# M480_v1 register map
File version: 1.0
Registers are 32-bit, read-write, reset 0x0 unless marked. A register's access mark holds for its fields unless they carry their own. Offsets are from the block's base; [hi:lo] are bit positions; {n}, {i} and the like mark numbered series.

## EMAC (part 1 of 2) — EMAC Register Map
Base 0x4000B000
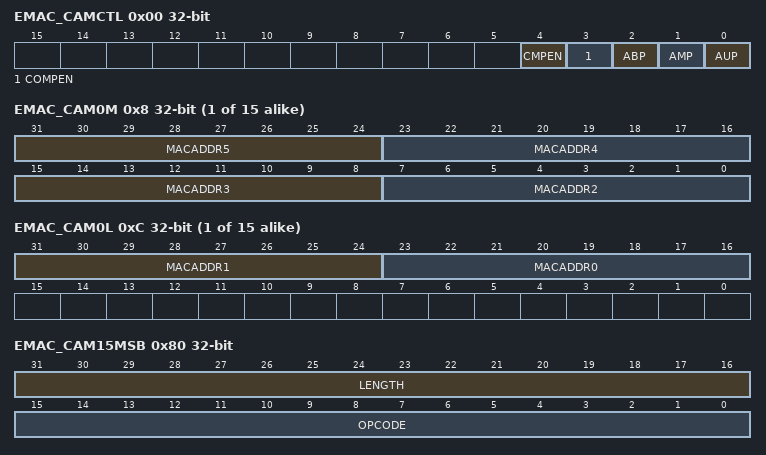
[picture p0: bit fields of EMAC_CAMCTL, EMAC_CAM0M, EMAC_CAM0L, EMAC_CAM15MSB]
0x00 EMAC_CAMCTL — CAM Comparison Control Register
  [4] CMPEN — CAM Compare Enable Bit. The CMPEN controls the enable of CAM comparison function for destination MAC address recognition. If software wants to receive a packet with specific destination MAC address, configures the MAC address into CAM 12~0, then enables that CAM entry and set CMPEN to 1.
    0=CAM comparison function for destination MAC address recognition Disabled; 1=CAM comparison function for destination MAC address recognition Enabled
  [3] COMPEN — Complement CAM Comparison Enable Bit. The COMPEN controls the complement of the CAM comparison result. If the CMPEN and COMPEN are both enabled, the incoming packet with specific destination MAC address configured in CAM entry will be dropped. And the incoming packet with destination MAC address does not configured in any CAM entry will be received.
    0=Complement CAM comparison result Disabled; 1=Complement CAM comparison result Enabled
  [2] ABP — Accept Broadcast Packet. The ABP controls the broadcast packet reception. If ABP is enabled, EMAC receives all incoming packet its destination MAC address is a broadcast address.
    0=EMAC receives packet depends on the CAM comparison result; 1=EMAC receives all broadcast packets
  [1] AMP — Accept Multicast Packet. The AMP controls the multicast packet reception. If AMP is enabled, EMAC receives all incoming packet its destination MAC address is a multicast address.
    0=EMAC receives packet depends on the CAM comparison result; 1=EMAC receives all multicast packets
  [0] AUP — Accept Unicast Packet. The AUP controls the unicast packet reception. If AUP is enabled, EMAC receives all incoming packet its destination MAC address is a unicast address.
    0=EMAC receives packet depends on the CAM comparison result; 1=EMAC receives all unicast packets
0x04 ECAM_CAMEN — CAM Enable Register
  [0] CAMxEN — CAM Entry X Enable Bit. The CAMxEN controls the validation of CAM entry x. The CAM entry 13, 14 and 15 are for PAUSE control frame transmission. If software wants to transmit a PAUSE control frame out to network, the enable bits of these three CAM entries all must be enabled first.
    0=CAM entry x Disabled; 1=CAM entry x Enabled
{0x8+8i} EMAC_CAM{i}M (i=0..14) — CAM{i} Most Significant Word Register
  [31:24] MACADDR5 — MAC Address Byte 5. The CAMxM keeps the bit 47~16 of MAC address. The x can be the 0~14. The register pair {EMAC_CAMxM, EMAC_CAMxL} represents a CAM entry and keeps a MAC address. For example, if the MAC address 00-50-BA-33-BA-44 kept in CAM entry 1, the register EMAC_CAM1M is 0x0050_BA33 and EMAC_CAM1L is 0xBA44_0000.
  [23:16] MACADDR4 — MAC Address Byte 4
  [15:8] MACADDR3 — MAC Address Byte 3
  [7:0] MACADDR2 — MAC Address Byte 2
{0xC+8i} EMAC_CAM{i}L (i=0..14) — CAM{i} Least Significant Word Register
  [31:24] MACADDR1 — MAC Address Byte 1. The CAMxL keeps the bit 15~0 of MAC address. The x can be the 0~14. The register pair {EMAC_CAMxM, EMAC_CAMxL} represents a CAM entry and keeps a MAC address. For example, if the MAC address 00-50-BA-33-BA-44 kept in CAM entry 1, the register EMAC_CAM1M is 0x0050_BA33 and EMAC_CAM1L is 0xBA44_0000.
  [23:16] MACADDR0 — MAC Address Byte 0
0x80 EMAC_CAM15MSB — CAM15 Most Significant Word Register
  [31:16] LENGTH — LENGTH Field of PAUSE Control Frame. In the PAUSE control frame, a LENGTH field defined and is 0x8808.
  [15:0] OPCODE — OP Code Field of PAUSE Control Frame. In the PAUSE control frame, an op code field defined and is 0x0001.
0x84 EMAC_CAM15LSB — CAM15 Least Significant Word Register
  [31:24] OPERAND — Pause Parameter. In the PAUSE control frame, an OPERAND field defined and controls how much time the destination Ethernet MAC Controller paused. The unit of the OPERAND is a slot time, the 512-bit time.
0x88 EMAC_TXDSA reset 0xFFFFFFFC — Transmit Descriptor Link List Start Address Register
  [31:0] TXDSA — Transmit Descriptor Link-list Start Address. The TXDSA keeps the start address of transmit descriptor link-list. If the software enables the bit TXON (EMAC_CTL[8]), the content of TXDSA will be loaded into the current transmit descriptor start address register (EMAC_CTXDSA). The TXDSA does not be updated by EMAC. During the operation, EMAC will ignore the bits [1:0] of TXDSA. This means that TX descriptors must locate at word boundary memory address.
0x8C EMAC_RXDSA reset 0xFFFFFFFC — Receive Descriptor Link List Start Address Register
  [31:0] RXDSA — Receive Descriptor Link-list Start Address. The RXDSA keeps the start address of receive descriptor link-list. If the S/W enables the bit RXON (EMAC_CTL[0]), the content of RXDSA will be loaded into the current receive descriptor start address register (EMAC_CRXDSA). The RXDSA does not be updated by EMAC. During the operation, EMAC will ignore the bits [1:0] of RXDSA. This means that RX descriptors must locate at word boundary memory address.
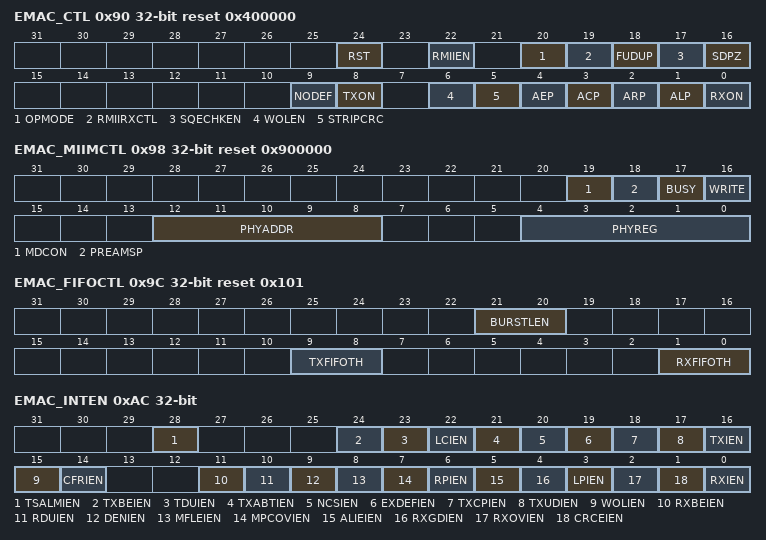
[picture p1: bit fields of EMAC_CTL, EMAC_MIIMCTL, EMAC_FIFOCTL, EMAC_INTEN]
0x90 EMAC_CTL reset 0x400000 — MAC Control Register
  [24] RST — Software Reset. The RST implements a reset function to make the EMAC return default state. The RST is a self-clear bit. This means after the software reset finished, the RST will be cleared automatically. Enable RST can also reset all control and status registers, exclusive of the control bits RMIIEN (EMAC_CTL[22]), and OPMODE (EMAC_CTL[20]). The EMAC re-initial is necessary after the software reset completed.
    0=Software reset completed; 1=Software reset Enabled
  [22] RMIIEN — RMII Mode Enable Bit. This bit controls if Ethernet MAC controller connected with off-chip Ethernet PHY by MII interface or RMII interface. The RST (EMAC_CTL[24]) would not affect RMIIEN value. Note: This field must keep 1.
    0=Ethernet MAC controller RMII mode Disabled; 1=Ethernet MAC controller RMII mode Enabled
  [20] OPMODE — Operation Mode Selection. The OPMODE defines that if the EMAC is operating on 10M or 100M bps mode. The RST (EMAC_CTL[24]) would not affect OPMODE value.
    0=EMAC operates in 10Mbps mode; 1=EMAC operates in 100Mbps mode
  [19] RMIIRXCTL — RMII RX Control. The RMIIRXCTL control the receive data sample in RMII mode. It's necessary to set this bit high when RMIIEN (EMAC_CTL[ [22]) is high.
    0=RMII RX control Disabled; 1=RMII RX control Enabled
  [18] FUDUP — Full Duplex Mode Selection. The FUDUP controls that if EMAC is operating on full or half duplex mode.
    0=EMAC operates in half duplex mode; 1=EMAC operates in full duplex mode
  [17] SQECHKEN — SQE Checking Enable Bit. The SQECHKEN controls the enable of SQE checking. The SQE checking is only available while EMAC is operating on 10M bps and half duplex mode. In other words, the SQECHKEN cannot affect EMAC operation, if the EMAC is operating on 100M bps or full duplex mode.
    0=SQE checking Disabled while EMAC is operating in 10Mbps and Half Duplex mode; 1=SQE checking Enabled while EMAC is operating in 10Mbps and Half Duplex mode
  [16] SDPZ — Send PAUSE Frame. The SDPZ controls the PAUSE control frame transmission. If S/W wants to send a PAUSE control frame out, the CAM entry 13, 14 and 15 must be configured first and the corresponding CAM enable bit of CAMEN register also must be set. Then, set SDPZ to 1 enables the PAUSE control frame transmission. The SDPZ is a self-clear bit. This means after the PAUSE control frame transmission has completed, the SDPZ will be cleared automatically. It is recommended that only enabling SNDPAUSE while EMAC is operating in Full Duplex mode.
    0=PAUSE control frame transmission completed; 1=PAUSE control frame transmission Enabled
  [9] NODEF — No Deferral. The NODEF controls the enable of deferral exceed counter. If NODEF is set to high, the deferral exceed counter is disabled. The NODEF is only useful while EMAC is operating on half duplex mode.
    0=The deferral exceed counter Enabled; 1=The deferral exceed counter Disabled
  [8] TXON — Frame Transmission ON. The TXON controls the normal packet transmission of EMAC. If the TXON is set to high, the EMAC starts the packet transmission process, including the TX descriptor fetching, packet transmission and TX descriptor modification. It is must to finish EMAC initial sequence before enable TXON. Otherwise, the EMAC operation is undefined. If the TXON is disabled during EMAC is transmitting a packet out, the EMAC stops the packet transmission process after the current packet transmission finished.
    0=Packet transmission process stopped; 1=Packet transmission process started
  [6] WOLEN — Wake on LAN Enable Bit. The WOLEN high enables the functionality that Ethernet MAC controller checked if the incoming packet is Magic Packet and wakeup system from Power-down mode. If incoming packet was a Magic Packet and the system was in Power-down, the Ethernet MAC controller would generate a wakeup event to wake system up from Power-down mode.
    0=Wake-up by Magic Packet function Disabled; 1=Wake-up by Magic Packet function Enabled
  [5] STRIPCRC — Strip CRC Checksum. The STRIPCRC controls if the length of incoming packet is calculated with 4 bytes CRC checksum. If the STRIPCRC is set to high, 4 bytes CRC checksum is excluded from length calculation of incoming packet.
    0=The 4 bytes CRC checksum is included in packet length calculation; 1=The 4 bytes CRC checksum is excluded in packet length calculation
  [4] AEP — Accept CRC Error Packet. The AEP controls the EMAC accepts or drops the CRC error packet. If the AEP is set to high, the incoming packet with CRC error will be received by EMAC as a good packet.
    0=Ethernet MAC controller dropped the CRC error packet; 1=Ethernet MAC controller received the CRC error packet
  [3] ACP — Accept Control Packet. The ACP controls the control frame reception. If the ACP is set to high, the EMAC will accept the control frame. Otherwise, the control frame will be dropped. It is recommended that S/W only enable ACP while EMAC is operating on full duplex mode.
    0=Ethernet MAC controller dropped the control frame; 1=Ethernet MAC controller received the control frame
  [2] ARP — Accept Runt Packet. The ARP controls the runt packet, which length is less than 64 bytes, reception. If the ARP is set to high, the EMAC will accept the runt packet. Otherwise, the runt packet will be dropped.
    0=Ethernet MAC controller dropped the runt packet; 1=Ethernet MAC controller received the runt packet
  [1] ALP — Accept Long Packet. The ALP controls the long packet, which packet length is greater than 1518 bytes, reception. If the ALP is set to high, the EMAC will accept the long packet. Otherwise, the long packet will be dropped.
    0=Ethernet MAC controller dropped the long packet; 1=Ethernet MAC controller received the long packet
  [0] RXON — Frame Reception ON. The RXON controls the normal packet reception of EMAC. If the RXON is set to high, the EMAC starts the packet reception process, including the RX descriptor fetching, packet reception and RX descriptor modification. It is necessary to finish EMAC initial sequence before enable RXON. Otherwise, the EMAC operation is undefined. If the RXON is disabled during EMAC is receiving an incoming packet, the EMAC stops the packet reception process after the current packet reception finished.
    0=Packet reception process stopped; 1=Packet reception process started
0x94 EMAC_MIIMDAT — MII Management Data Register
  [15:0] DATA — MII Management Data. The DATA is the 16 bits data that will be written into the registers of external PHY for MII Management write command or the data from the registers of external PHY for MII Management read command.
0x98 EMAC_MIIMCTL reset 0x900000 — MII Management Control and Address Register
  [19] MDCON — MDC Clock ON. The MDC controls the MDC clock generation. If the MDCON is set to high, the MDC clock is turned on.
    0=MDC clock off; 1=MDC clock on
  [18] PREAMSP — Preamble Suppress. The PREAMSP controls the preamble field generation of MII management frame. If the PREAMSP is set to high, the preamble field generation of MII management frame is skipped.
    0=Preamble field generation of MII management frame not skipped; 1=Preamble field generation of MII management frame skipped
  [17] BUSY — Busy Bit. The BUSY controls the enable of the MII management frame generation. If S/W wants to access registers of external PHY, it set BUSY to high and EMAC generates the MII management frame to external PHY through MII Management I/F. The BUSY is a self-clear bit. This means the BUSY will be cleared automatically after the MII management command finished.
    0=MII management command generation finished; 1=MII management command generation Enabled
  [16] WRITE — Write Command. The Write defines the MII management command is a read or write.
    0=MII management command is a read command; 1=MII management command is a write command
  [12:8] PHYADDR — PHY Address. The PHYADDR keeps the address to differentiate which external PHY is the target of the MII management command.
  [4:0] PHYREG — PHY Register Address. The PHYREG keeps the address to indicate which register of external PHY is the target of the MII management command.
0x9C EMAC_FIFOCTL reset 0x101 — FIFO Threshold Control Register
  [21:20] BURSTLEN — DMA Burst Length. This defines the burst length of AHB bus cycle while EMAC accesses system memory.
    0=4 words; 1=8 words; 2=16 words; 3=16 words
  [9:8] TXFIFOTH — TXFIFO Low Threshold. The TXFIFOTH controls when TXDMA requests internal arbiter for data transfer between system memory and TXFIFO. The TXFIFOTH defines not only the low threshold of TXFIFO, but also the high threshold. The high threshold is the twice of low threshold always. During the packet transmission, if the TXFIFO reaches the high threshold, the TXDMA stops generate request to transfer frame data from system memory to TXFIFO. If the frame data in TXFIFO is less than low threshold, TXDMA starts to transfer frame data from system memory to TXFIFO. The TXFIFOTH also defines when the TXMAC starts to transmit frame out to network. The TXMAC starts to transmit the frame out while the TXFIFO first time reaches the high threshold during the transmission of the frame. If the frame data length is less than TXFIFO high threshold, the TXMAC starts to transmit the frame out after the frame data are all inside the TXFIFO.
    0=Undefined; 1=TXFIFO low threshold is 64B and high threshold is 128B; 2=TXFIFO low threshold is 80B and high threshold is 160B; 3=TXFIFO low threshold is 96B and high threshold is 192B
  [1:0] RXFIFOTH — RXFIFO Low Threshold. The RXFIFOTH controls when RXDMA requests internal arbiter for data transfer between RXFIFO and system memory. The RXFIFOTH defines not only the high threshold of RXFIFO, but also the low threshold. The low threshold is the half of high threshold always. During the packet reception, if the RXFIFO reaches the high threshold, the RXDMA starts to transfer frame data from RXFIFO to system memory. If the frame data in RXFIFO is less than low threshold, RXDMA stops to transfer the frame data to system memory.
    0=Depend on the burst length setting. If the burst length is 8 words, high threshold is 8 words, too; 1=RXFIFO high threshold is 64B and low threshold is 32B; 2=RXFIFO high threshold is 128B and low threshold is 64B; 3=RXFIFO high threshold is 192B and low threshold is 96B
0xA0 EMAC_TXST wo reset not defined — Transmit Start Demand Register
  [31:0] TXST — Transmit Start Demand. If the TX descriptor is not available for use of TXDMA after the TXON (EMAC_CTL[8]) is enabled, the FSM (Finite State Machine) of TXDMA enters the Halt state and the frame transmission is halted. After the S/W has prepared the new TX descriptor for frame transmission, it must issue a write command to EMAC_TXST register to make TXDMA to leave Halt state and continue the frame transmission. The EMAC_TXST is a write only register and read from this register is undefined. The write to EMAC_TXST register takes effect only when TXDMA stayed at Halt state.
0xA4 EMAC_RXST wo reset not defined — Receive Start Demand Register
  [31:0] RXST — Receive Start Demand. If the RX descriptor is not available for use of RXDMA after the RXON (EMAC_CTL[0]) is enabled, the FSM (Finite State Machine) of RXDMA enters the Halt state and the frame reception is halted. After the S/W has prepared the new RX descriptor for frame reception, it must issue a write command to EMAC_RXST register to make RXDMA to leave Halt state and continue the frame reception. The EMAC_RXST is a write only register and read from this register is undefined. The write to EMAC_RXST register take effect only when RXDMA stayed at Halt state.
0xA8 EMAC_MRFL reset 0x800 — Maximum Receive Frame Control Register
  [15:0] MRFL — Maximum Receive Frame Length. The MRFL defines the maximum frame length for received frame. If the frame length of received frame is greater than MRFL, and bit MFLEIEN (EMAC_INTEN[8]) is also enabled, the bit MFLEIF (EMAC_INTSTS[8]) is set and the RX interrupt is triggered. It is recommended that only use MRFL to qualify the length of received frame while S/W wants to receive a frame which length is greater than 1518 bytes.
0xAC EMAC_INTEN — MAC Interrupt Enable Register
  [28] TSALMIEN — Time Stamp Alarm Interrupt Enable Bit. The TSALMIEN controls the TSALMIF (EMAC_INTSTS[28]) interrupt generation. If TSALMIF (EMAC_INTSTS[28]) is set, and both TSALMIEN and TXIEN (EMAC_INTEN[16]) enabled, the EMAC generates the TX interrupt to CPU. If TSALMIEN or TXIEN (EMAC_INTEN[16]) disabled, no TX interrupt generated to CPU even the TXTSALMIF (EMAC_INTEN[28]) is set.
    0=TXTSALMIF (EMAC_INTSTS[28]) trigger TX interrupt Disabled; 1=TXTSALMIF (EMAC_INTSTS[28]) trigger TX interrupt Enabled
  [24] TXBEIEN — Transmit Bus Error Interrupt Enable Bit. The TXBEIEN controls the TXBEIF (EMAC_INTSTS[24]) interrupt generation. If TXBEIF (EMAC_INTSTS[24]) is set, and both TXBEIEN and TXIEN (EMAC_INTEN[16]) are enabled, the EMAC generates the TX interrupt to CPU. If TXBEIEN or TXIEN (EMAC_INTEN[16]) is disabled, no TX interrupt is generated to CPU even the TXBEIF (EMAC_INTSTS[24]) is set.
    0=TXBEIF (EMAC_INTSTS[24]) trigger TX interrupt Disabled; 1=TXBEIF (EMAC_INTSTS[24]) trigger TX interrupt Enabled
  [23] TDUIEN — Transmit Descriptor Unavailable Interrupt Enable Bit. The TDUIEN controls the TDUIF (EMAC_INTSTS[23]) interrupt generation. If TDUIF (EMAC_INTSTS[23]) is set, and both TDUIEN and TXIEN (EMAC_INTEN[16]) are enabled, the EMAC generates the TX interrupt to CPU. If TDUIEN or TXIEN (EMAC_INTEN[16]) is disabled, no TX interrupt is generated to CPU even the TDUIF (EMAC_INTSTS[23]) is set.
    0=TDUIF (EMAC_INTSTS[23]) trigger TX interrupt Disabled; 1=TDUIF (EMAC_INTSTS[23]) trigger TX interrupt Enabled
  [22] LCIEN — Late Collision Interrupt Enable Bit. The LCIEN controls the LCIF (EMAC_INTSTS[22]) interrupt generation. If LCIF (EMAC_INTSTS[22]) is set, and both LCIEN and TXIEN (EMAC_INTEN[16]) are enabled, the EMAC generates the TX interrupt to CPU. If LCIEN or TXIEN (EMAC_INTEN[16]) is disabled, no TX interrupt is generated to CPU even the LCIF (EMAC_INTSTS[22]) is set.
    0=LCIF (EMAC_INTSTS[22]) trigger TX interrupt Disabled; 1=LCIF (EMAC_INTSTS[22]) trigger TX interrupt Enabled
  [21] TXABTIEN — Transmit Abort Interrupt Enable Bit. The TXABTIEN controls the TXABTIF (EMAC_INTSTS[21]) interrupt generation. If TXABTIF (EMAC_INTSTS[21]) is set, and both TXABTIEN and TXIEN (EMAC_INTEN[16]) are enabled, the EMAC generates the TX interrupt to CPU. If TXABTIEN or TXIEN (EMAC_INTEN[16]) is disabled, no TX interrupt is generated to CPU even the TXABTIF (EMAC_INTSTS[21]) is set.
    0=TXABTIF (EMAC_INTSTS[21]) trigger TX interrupt Disabled; 1=TXABTIF (EMAC_INTSTS[21]) trigger TX interrupt Enabled
  [20] NCSIEN — No Carrier Sense Interrupt Enable Bit. The NCSIEN controls the NCSIF (EMAC_INTSTS[20]) interrupt generation. If NCSIF (EMAC_INTSTS[20]) is set, and both NCSIEN and TXIEN (EMAC_INTEN[16]) are enabled, the EMAC generates the TX interrupt to CPU. If NCSIEN or TXIEN (EMAC_INTEN[16]) is disabled, no TX interrupt is generated to CPU even the NCSIF (EMAC_INTSTS[20]) is set.
    0=NCSIF (EMAC_INTSTS[20]) trigger TX interrupt Disabled; 1=NCSIF (EMAC_INTSTS[20]) trigger TX interrupt Enabled
  [19] EXDEFIEN — Defer Exceed Interrupt Enable Bit. The EXDEFIEN controls the EXDEFIF (EMAC_INTSTS[19]) interrupt generation. If EXDEFIF (EMAC_INTSTS[19]) is set, and both EXDEFIEN and TXIEN (EMAC_INTEN[16]) are enabled, the EMAC generates the TX interrupt to CPU. If EXDEFIEN or TXIEN (EMAC_INTEN[16]) is disabled, no TX interrupt is generated to CPU even the EXDEFIF (EMAC_INTSTS[19]) is set.
    0=EXDEFIF (EMAC_INTSTS[19]) trigger TX interrupt Disabled; 1=EXDEFIF (EMAC_INTSTS[19]) trigger TX interrupt Enabled
  [18] TXCPIEN — Transmit Completion Interrupt Enable Bit. The TXCPIEN controls the TXCPIF (EMAC_INTSTS[18]) interrupt generation. If TXCPIF (EMAC_INTSTS[18]) is set, and both TXCPIEN and TXIEN (EMAC_INTEN[16]) are enabled, the EMAC generates the TX interrupt to CPU. If TXCPIEN or TXIEN (EMAC_INTEN[16]) is disabled, no TX interrupt is generated to CPU even the TXCPIF (EMAC_INTSTS[18]) is set.
    0=TXCPIF (EMAC_INTSTS[18]) trigger TX interrupt Disabled; 1=TXCPIF (EMAC_INTSTS[18]) trigger TX interrupt Enabled
  [17] TXUDIEN — Transmit FIFO Underflow Interrupt Enable Bit. The TXUDIEN controls the TXUDIF (EMAC_INTSTS[17]) interrupt generation. If TXUDIF (EMAC_INTSTS[17]) is set, and both TXUDIEN and TXIEN (EMAC_INTEN[16]) are enabled, the EMAC generates the TX interrupt to CPU. If TXUDIEN or TXIEN (EMAC_INTEN[16]) is disabled, no TX interrupt is generated to CPU even the TXUDIF (EMAC_INTSTS[17]) is set.
    0=TXUDIF (EMAC_INTSTS[17]) TX interrupt Disabled; 1=TXUDIF (EMAC_INTSTS[17]) TX interrupt Enabled
  [16] TXIEN — Transmit Interrupt Enable Bit. The TXIEN controls the TX interrupt generation. If TXIEN is enabled and TXIF (EMAC_INTSTS[16]) is high, EMAC generates the TX interrupt to CPU. If TXIEN is disabled, no TX interrupt is generated to CPU even any status bit of EMAC_INTSTS[24:17] set and the corresponding bit of EMAC_INTEN is enabled. In other words, if S/W wants to receive TX interrupt from EMAC, this bit must be enabled. And, if S/W doesn't want to receive any TX interrupt from EMAC, disables this bit.
    0=TXIF (EMAC_INTSTS[16]) is masked and TX interrupt generation Disabled; 1=TXIF (EMAC_INTSTS[16]) is not masked and TX interrupt generation Enabled
  [15] WOLIEN — Wake on LAN Interrupt Enable Bit. The WOLIEN controls the WOLIF (EMAC_INTSTS[15]) interrupt generation. If WOLIF (EMAC_INTSTS[15]) is set, and both WOLIEN and RXIEN (EMAC_INTEN[0]) are enabled, the EMAC generates the RX interrupt to CPU. If WOLIEN or RXIEN (EMAC_INTEN[0]) is disabled, no RX interrupt is generated to CPU even the WOLIF (EMAC_INTSTS[15]) is set.
    0=WOLIF (EMAC_INTSTS[15]) trigger RX interrupt Disabled; 1=WOLIF (EMAC_INTSTS[15]) trigger RX interrupt Enabled
  [14] CFRIEN — Control Frame Receive Interrupt Enable Bit. The CFRIEN controls the CFRIF (EMAC_INTSTS[14]) interrupt generation. If CFRIF (EMAC_INTSTS[14]) is set, and both CFRIEN and RXIEN (EMAC_INTEN[0]) are enabled, the EMAC generates the RX interrupt to CPU. If CFRIEN or RXIEN (EMAC_INTEN[0]) is disabled, no RX interrupt is generated to CPU even the CFRIF (EMAC_INTSTS[14]) register is set.
    0=CFRIF (EMAC_INTSTS[14]) trigger RX interrupt Disabled; 1=CFRIF (EMAC_INTSTS[14]) trigger RX interrupt Enabled
  [11] RXBEIEN — Receive Bus Error Interrupt Enable Bit. The RXBEIEN controls the RXBEIF (EMAC_INTSTS[11]) interrupt generation. If RXBEIF (EMAC_INTSTS[11]) is set, and both RXBEIEN and RXIEN (EMAC_INTEN[0]) are enabled, the EMAC generates the RX interrupt to CPU. If RXBEIEN or RXIEN (EMAC_INTEN[0]) is disabled, no RX interrupt is generated to CPU even the RXBEIF (EMAC_INTSTS[11]) is set.
    0=RXBEIF (EMAC_INTSTS[11]) trigger RX interrupt Disabled; 1=RXBEIF (EMAC_INTSTS[11]) trigger RX interrupt Enabled
  [10] RDUIEN — Receive Descriptor Unavailable Interrupt Enable Bit. The RDUIEN controls the RDUIF (EMAC_INTSTS[10]) interrupt generation. If RDUIF (EMAC_INTSTS[10]) is set, and both RDUIEN and RXIEN (EMAC_INTEN[0]) are enabled, the EMAC generates the RX interrupt to CPU. If RDUIEN or RXIEN (EMAC_INTEN[0]) is disabled, no RX interrupt is generated to CPU even the RDUIF (EMAC_MIOSTA[10]) register is set.
    0=RDUIF (EMAC_INTSTS[10]) trigger RX interrupt Disabled; 1=RDUIF (EMAC_INTSTS[10]) trigger RX interrupt Enabled
  [9] DENIEN — DMA Early Notification Interrupt Enable Bit. The DENIEN controls the DENIF (EMAC_INTSTS[9]) interrupt generation. If DENIF (EMAC_INTSTS[9]) is set, and both DENIEN and RXIEN (EMAC_INTEN[0]) are enabled, the EMAC generates the RX interrupt to CPU. If DENIEN or RXIEN (EMAC_INTEN[0]) is disabled, no RX interrupt is generated to CPU even the DENIF (EMAC_INTSTS[9]) is set.
    0=TDENIF (EMAC_INTSTS[9]) trigger RX interrupt Disabled; 1=TDENIF (EMAC_INTSTS[9]) trigger RX interrupt Enabled
  [8] MFLEIEN — Maximum Frame Length Exceed Interrupt Enable Bit. The MFLEIEN controls the MFLEIF (EMAC_INTSTS[8]) interrupt generation. If MFLEIF (EMAC_INTSTS[8]) is set, and both MFLEIEN and RXIEN (EMAC_INTEN[0]) are enabled, the EMAC generates the RX interrupt to CPU. If MFLEIEN or RXIEN (EMAC_INTEN[0]) is disabled, no RX interrupt is generated to CPU even the MFLEIF (EMAC_INTSTS[8]) is set.
    0=MFLEIF (EMAC_INTSTS[8]) trigger RX interrupt Disabled; 1=MFLEIF (EMAC_INTSTS[8]) trigger RX interrupt Enabled
  [7] MPCOVIEN — Miss Packet Counter Overrun Interrupt Enable Bit. The MPCOVIEN controls the MPCOVIF (EMAC_INTSTS[7]) interrupt generation. If MPCOVIF (EMAC_INTSTS[7]) is set, and both MPCOVIEN and RXIEN (EMAC_INTEN[0]) are enabled, the EMAC generates the RX interrupt to CPU. If MPCOVIEN or RXIEN (EMAC_INTEN[0]) is disabled, no RX interrupt is generated to CPU even the MPCOVIF (EMAC_INTSTS[7]) is set.
    0=MPCOVIF (EMAC_INTSTS[7]) trigger RX interrupt Disabled; 1=MPCOVIF (EMAC_INTSTS[7]) trigger RX interrupt Enabled
  [6] RPIEN — Runt Packet Interrupt Enable Bit. The RPIEN controls the RPIF (EMAC_INTSTS[6]) interrupt generation. If RPIF (EMAC_INTSTS[6]) is set, and both RPIEN and RXIEN (EMAC_INTEN[0]) are enabled, the EMAC generates the RX interrupt to CPU. If RPIEN or RXIEN (EMAC_INTEN[0]) is disabled, no RX interrupt is generated to CPU even the RPIF (EMAC_INTSTS[6]) is set.
    0=RPIF (EMAC_INTSTS[6]) trigger RX interrupt Disabled; 1=RPIF (EMAC_INTSTS[6]) trigger RX interrupt Enabled
  [5] ALIEIEN — Alignment Error Interrupt Enable Bit. The ALIEIEN controls the ALIEIF (EMAC_INTSTS[5]) interrupt generation. If ALIEIF (EMAC_INTSTS[5]) is set, and both ALIEIEN and RXIEN (EMAC_INTEN[0]) are enabled, the EMAC generates the RX interrupt to CPU. If ALIEIEN or RXIEN (EMAC_INTEN[0]) is disabled, no RX interrupt is generated to CPU even the ALIEIF (EMAC_INTSTS[5]) is set.
    0=ALIEIF (EMAC_INTSTS[5]) trigger RX interrupt Disabled; 1=ALIEIF (EMAC_INTSTS[5]) trigger RX interrupt Enabled
  [4] RXGDIEN — Receive Good Interrupt Enable Bit. The RXGDIEN controls the RXGDIF (EMAC_INTSTS[4]) interrupt generation. If RXGDIF (EMAC_INTSTS[4]) is set, and both RXGDIEN and RXIEN (EMAC_INTEN[0]) are enabled, the EMAC generates the RX interrupt to CPU. If RXGDIEN or RXIEN (EMAC_INTEN[0]) is disabled, no RX interrupt is generated to CPU even the RXGDIF (EMAC_INTSTS[4]) is set.
    0=RXGDIF (EMAC_INTSTS[4]) trigger RX interrupt Disabled; 1=RXGDIF (EMAC_INTSTS[4]) trigger RX interrupt Enabled
  [3] LPIEN — Long Packet Interrupt Enable Bit. The LPIEN controls the LPIF (EMAC_INTSTS[3]) interrupt generation. If LPIF (EMAC_INTSTS[3]) is set, and both LPIEN and RXIEN (EMAC_INTEN[0]) are enabled, the EMAC generates the RX interrupt to CPU. If LPIEN or RXIEN (EMAC_INTEN[0]) is disabled, no RX interrupt is generated to CPU even the LPIF (EMAC_INTSTS[3]) is set.
    0=LPIF (EMAC_INTSTS[3]) trigger RX interrupt Disabled; 1=LPIF (EMAC_INTSTS[3]) trigger RX interrupt Enabled
  [2] RXOVIEN — Receive FIFO Overflow Interrupt Enable Bit. The RXOVIEN controls the RXOVIF (EMAC_INTSTS[2]) interrupt generation. If RXOVIF (EMAC_INTSTS[2]) is set, and both RXOVIEN and RXIEN (EMAC_INTEN[0]) are enabled, the EMAC generates the RX interrupt to CPU. If RXOVIEN or RXIEN (EMAC_INTEN[0]) is disabled, no RX interrupt is generated to CPU even the RXOVIF (EMAC_INTSTS[2]) is set.
    0=RXOVIF (EMAC_INTSTS[2]) trigger RX interrupt Disabled; 1=RXOVIF (EMAC_INTSTS[2]) trigger RX interrupt Enabled
  [1] CRCEIEN — CRC Error Interrupt Enable Bit. The CRCEIEN controls the CRCEIF (EMAC_INTSTS[1]) interrupt generation. If CRCEIF (EMAC_INTSTS[1]) is set, and both CRCEIEN and RXIEN (EMAC_INTEN[0]) are enabled, the EMAC generates the RX interrupt to CPU. If CRCEIEN or RXIEN (EMAC_INTEN[0]) is disabled, no RX interrupt is generated to CPU even the CRCEIF (EMAC_INTSTS[1]) is set.
    0=CRCEIF (EMAC_INTSTS[1]) trigger RX interrupt Disabled; 1=CRCEIF (EMAC_INTSTS[1]) trigger RX interrupt Enabled
  [0] RXIEN — Receive Interrupt Enable Bit. The RXIEN controls the RX interrupt generation. If RXIEN is enabled and RXIF (EMAC_INTSTS[0]) is high, EMAC generates the RX interrupt to CPU. If RXIEN is disabled, no RX interrupt is generated to CPU even any status bit EMAC_INTSTS[15:1] is set and the corresponding bit of EMAC_INTEN is enabled. In other words, if S/W wants to receive RX interrupt from EMAC, this bit must be enabled. And, if S/W doesn't want to receive any RX interrupt from EMAC, disables this bit.
    0=RXIF (EMAC_INTSTS[0]) is masked and RX interrupt generation Disabled; 1=RXIF (EMAC_INTSTS[0]) is not masked and RX interrupt generation Enabled
